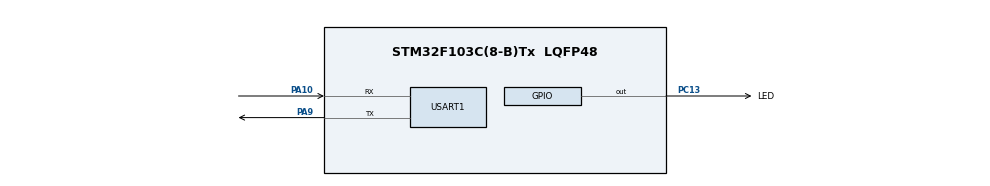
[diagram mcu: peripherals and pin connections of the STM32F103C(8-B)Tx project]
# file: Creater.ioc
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FREERTOS.BinarySemaphores01=osSema_Ex,Dynamic,NULL
FREERTOS.Mutexes01=osMu_Ex,Dynamic,NULL
FREERTOS.Tasks01=defaultTask,24,128,StartDefaultTask,Default,NULL,Dynamic,NULL,NULL
Mcu.Family=STM32F1
Mcu.Name=STM32F103C(8-B)Tx
Mcu.Package=LQFP48
NVIC.PriorityGroup=NVIC_PRIORITYGROUP_4
NVIC.USART1_IRQn=true\:0\:0\:false\:false\:true\:true\:true\:true
PA10.Mode=Asynchronous
PA10.Signal=USART1_RX
PA13.Mode=Serial_Wire
PA13.Signal=SYS_JTMS-SWDIO
PA14.Mode=Serial_Wire
PA14.Signal=SYS_JTCK-SWCLK
PA9.Mode=Asynchronous
PA9.Signal=USART1_TX
PC13-TAMPER-RTC.GPIO_Label=LED
PC13-TAMPER-RTC.Signal=GPIO_Output
ProjectManager.HeapSize=0x200
ProjectManager.StackSize=0x400
ProjectManager.TargetToolchain=Makefile
RCC.APB1Freq_Value=8000000
RCC.APB2Freq_Value=8000000
USART1.VirtualMode=VM_ASYNC
VP_FREERTOS_VS_CMSIS_V2.Mode=CMSIS_V2
board=custom

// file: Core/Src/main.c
/* USER CODE BEGIN Header */
/**
  ******************************************************************************
  * @file           : main.c
  * @brief          : Main program body
  ******************************************************************************
  * @attention
  *
  * <h2><center>&copy; Copyright (c) 2020 STMicroelectronics.
  * All rights reserved.</center></h2>
  *
  * This software component is licensed by ST under Ultimate Liberty license
  * SLA0044, the "License"; You may not use this file except in compliance with
  * the License. You may obtain a copy of the License at:
  *                             www.st.com/SLA0044
  *
  ******************************************************************************
  */
 #include "mainRTOS.h"
/* USER CODE END Header */
#include "main.h"
#include "cmsis_os.h"

/* USER CODE BEGIN PTD */

// stack dung luu dia chi chuong trinh, bien cuc bo, Vùng nhớ được cấp phát khi chương trình được biên dịch.
// Heap dung luu cac mang, cacs bien duoc cap phat Dynamic memory allocation,Vùng nhớ được cấp phát khi chạy chương trình (run-time).
/* USER CODE END PTD */

UART_HandleTypeDef huart1;

/* Definitions for defaultTask */
osThreadId_t defaultTaskHandle;
const osThreadAttr_t defaultTask_attributes = {
  .name = "defaultTask",
  .priority = (osPriority_t) osPriorityNormal,
  .stack_size = 128 * 4
};
/* Definitions for osMu_Ex */
osMutexId_t osMu_ExHandle;
const osMutexAttr_t osMu_Ex_attributes = {
  .name = "osMu_Ex"
};
/* Definitions for osSema_Ex */
osSemaphoreId_t osSema_ExHandle;
const osSemaphoreAttr_t osSema_Ex_attributes = {
  .name = "osSema_Ex"
};

void SystemClock_Config(void);
static void MX_GPIO_Init(void);
static void MX_USART1_UART_Init(void);
void StartDefaultTask(void *argument);

int main(void)
{

  /* MCU Configuration--------------------------------------------------------*/

  /* Reset of all peripherals, Initializes the Flash interface and the Systick. */
  HAL_Init();

  /* Configure the system clock */
  SystemClock_Config();

  /* Initialize all configured peripherals */
  MX_GPIO_Init();
  MX_USART1_UART_Init();

  /* Init scheduler */
  osKernelInitialize();
  /* Create the mutex(es) */
  /* creation of osMu_Ex */
  osMu_ExHandle = osMutexNew(&osMu_Ex_attributes);

  /* Create the semaphores(s) */
  /* creation of osSema_Ex */
  osSema_ExHandle = osSemaphoreNew(1, 1, &osSema_Ex_attributes);

  /* Create the thread(s) */
  /* creation of defaultTask */
  defaultTaskHandle = osThreadNew(StartDefaultTask, NULL, &defaultTask_attributes);

  /* Start scheduler */
  osKernelStart();

  /* We should never get here as control is now taken by the scheduler */
  /* Infinite loop */
  while (1)
  {

  }
}

void SystemClock_Config(void)
{
  RCC_OscInitTypeDef RCC_OscInitStruct = {0};
  RCC_ClkInitTypeDef RCC_ClkInitStruct = {0};

  /** Initializes the RCC Oscillators according to the specified parameters
  * in the RCC_OscInitTypeDef structure.
  */
  RCC_OscInitStruct.OscillatorType = RCC_OSCILLATORTYPE_HSI;
  RCC_OscInitStruct.HSIState = RCC_HSI_ON;
  RCC_OscInitStruct.HSICalibrationValue = RCC_HSICALIBRATION_DEFAULT;
  RCC_OscInitStruct.PLL.PLLState = RCC_PLL_NONE;
  if (HAL_RCC_OscConfig(&RCC_OscInitStruct) != HAL_OK)
  {
    Error_Handler();
  }
  /** Initializes the CPU, AHB and APB buses clocks
  */
  RCC_ClkInitStruct.ClockType = RCC_CLOCKTYPE_HCLK|RCC_CLOCKTYPE_SYSCLK
                              |RCC_CLOCKTYPE_PCLK1|RCC_CLOCKTYPE_PCLK2;
  RCC_ClkInitStruct.SYSCLKSource = RCC_SYSCLKSOURCE_HSI;
  RCC_ClkInitStruct.AHBCLKDivider = RCC_SYSCLK_DIV1;
  RCC_ClkInitStruct.APB1CLKDivider = RCC_HCLK_DIV1;
  RCC_ClkInitStruct.APB2CLKDivider = RCC_HCLK_DIV1;

  if (HAL_RCC_ClockConfig(&RCC_ClkInitStruct, FLASH_LATENCY_0) != HAL_OK)
  {
    Error_Handler();
  }
}

static void MX_USART1_UART_Init(void)
{

  huart1.Instance = USART1;
  huart1.Init.BaudRate = 115200;
  huart1.Init.WordLength = UART_WORDLENGTH_8B;
  huart1.Init.StopBits = UART_STOPBITS_1;
  huart1.Init.Parity = UART_PARITY_NONE;
  huart1.Init.Mode = UART_MODE_TX_RX;
  huart1.Init.HwFlowCtl = UART_HWCONTROL_NONE;
  huart1.Init.OverSampling = UART_OVERSAMPLING_16;
  if (HAL_UART_Init(&huart1) != HAL_OK)
  {
    Error_Handler();
  }

}

static void MX_GPIO_Init(void)
{
  GPIO_InitTypeDef GPIO_InitStruct = {0};

  /* GPIO Ports Clock Enable */
  __HAL_RCC_GPIOC_CLK_ENABLE();
  __HAL_RCC_GPIOA_CLK_ENABLE();

  /*Configure GPIO pin Output Level */
  HAL_GPIO_WritePin(LED_GPIO_Port, LED_Pin, GPIO_PIN_RESET);

  /*Configure GPIO pin : LED_Pin */
  GPIO_InitStruct.Pin = LED_Pin;
  GPIO_InitStruct.Mode = GPIO_MODE_OUTPUT_PP;
  GPIO_InitStruct.Pull = GPIO_NOPULL;
  GPIO_InitStruct.Speed = GPIO_SPEED_FREQ_LOW;
  HAL_GPIO_Init(LED_GPIO_Port, &GPIO_InitStruct);

}

void StartDefaultTask(void *argument)
{
  /* USER CODE BEGIN 5 */
  /* Infinite loop */

    mainRTOS();
    vTaskDelete(defaultTaskHandle);

  /* USER CODE END 5 */
}

void Error_Handler(void)
{
}

/************************ (C) COPYRIGHT STMicroelectronics *****END OF FILE****/
